AUTOSAR XML (schema 00047)
package /ETAS_BIP
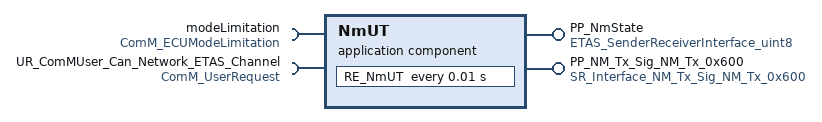
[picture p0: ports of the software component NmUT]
  application sw component type NmUT
    require port modeLimitation: required-interface=ComM_ECUModeLimitation
    require port UR_ComMUser_Can_Network_ETAS_Channel: required-interface=ComM_UserRequest
    provide port PP_NmState: provided-interface=ETAS_SenderReceiverInterface_uint8
    provide port PP_NM_Tx_Sig_NM_Tx_0x600: provided-interface=SR_Interface_NM_Tx_Sig_NM_Tx_0x600
    behavior IB_NmUT: data-type-mapping=ComMModeMapping
      timing event TE_ASW_Nm_10ms: start-on-event=RE_NmUT, period=0.01
      runnable RE_NmUT: symbol=RE_NmUT_func
        data-send-points:
          access DSP_uint8_1: accessed-variable=PP_NmState.uint8
          access DSP_NM_Tx_Sig_NM_Tx_0x600_0: accessed-variable=PP_NM_Tx_Sig_NM_Tx_0x600.NM_Tx_Sig_NM_Tx_0x600
        8 x sync call:
          SynchronousServerCallPoint_0: operation=modeLimitation.LimitECUToNoComMode
          SynchronousServerCallPoint_1: operation=modeLimitation.ReadInhibitCounter
          SynchronousServerCallPoint_2: operation=modeLimitation.ResetInhibitCounter
          SynchronousServerCallPoint_3: operation=modeLimitation.SetECUGroupClassification
          SynchronousServerCallPoint_4: operation=UR_ComMUser_Can_Network_ETAS_Channel.GetCurrentComMode
          SynchronousServerCallPoint_5: operation=UR_ComMUser_Can_Network_ETAS_Channel.GetMaxComMode
          SynchronousServerCallPoint_6: operation=UR_ComMUser_Can_Network_ETAS_Channel.GetRequestedComMode
          SynchronousServerCallPoint_7: operation=UR_ComMUser_Can_Network_ETAS_Channel.RequestComMode
